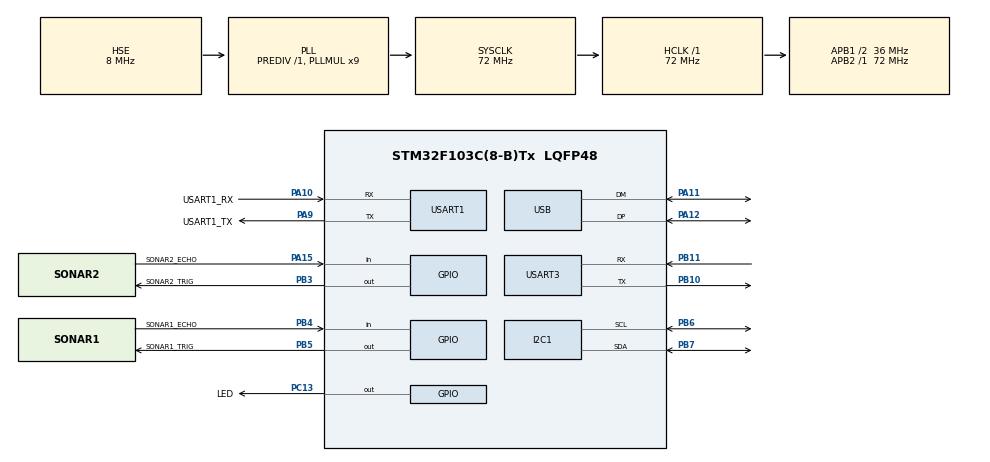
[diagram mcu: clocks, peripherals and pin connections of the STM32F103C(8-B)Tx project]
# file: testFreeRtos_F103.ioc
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FREERTOS.Tasks01=defaultTask,24,128,StartDefaultTask,Default,NULL,Dynamic,NULL,NULL;tsk_screen,8,512,tsk_screen_fn,Default,NULL,Dynamic,NULL,NULL;tsk_sensors,8,256,tsk_sensors_fn,Default,NULL,Dynamic,NULL,NULL
FREERTOS.Timers01=tmr_1,tmr_1_cb,osTimerPeriodic,Default,NULL,Dynamic,NULL
FREERTOS.configTOTAL_HEAP_SIZE=5120
FREERTOS.configUSE_NEWLIB_REENTRANT=1
I2C1.I2C_Mode=I2C_Fast
Mcu.Family=STM32F1
Mcu.Name=STM32F103C(8-B)Tx
Mcu.Package=LQFP48
NVIC.PriorityGroup=NVIC_PRIORITYGROUP_4
NVIC.TIM4_IRQn=true\:15\:0\:false\:false\:true\:false\:false\:true\:true
NVIC.TimeBase=TIM4_IRQn
NVIC.TimeBaseIP=TIM4
NVIC.USB_HP_CAN1_TX_IRQn=true\:5\:0\:false\:false\:true\:true\:true\:true\:true
NVIC.USB_LP_CAN1_RX0_IRQn=true\:5\:0\:false\:false\:true\:true\:false\:true\:true
PA10.GPIO_Label=USART1_RX
PA10.Mode=Asynchronous
PA10.Signal=USART1_RX
PA11.Mode=Device
PA11.Signal=USB_DM
PA12.Mode=Device
PA12.Signal=USB_DP
PA13.Mode=Serial_Wire
PA13.Signal=SYS_JTMS-SWDIO
PA14.Mode=Serial_Wire
PA14.Signal=SYS_JTCK-SWCLK
PA15.GPIO_Label=SONAR2_ECHO
PA15.Signal=GPIO_Input
PA9.GPIO_Label=USART1_TX
PA9.Mode=Asynchronous
PA9.Signal=USART1_TX
PB10.Mode=Asynchronous
PB10.Signal=USART3_TX
PB11.Mode=Asynchronous
PB11.Signal=USART3_RX
PB3.GPIO_Label=SONAR2_TRIG
PB3.Signal=GPIO_Output
PB4.GPIO_Label=SONAR1_ECHO
PB4.Signal=GPIO_Input
PB5.GPIO_Label=SONAR1_TRIG
PB5.Signal=GPIO_Output
PB6.Mode=I2C
PB6.Signal=I2C1_SCL
PB7.Mode=I2C
PB7.Signal=I2C1_SDA
PC13-TAMPER-RTC.GPIO_Label=LED
PC13-TAMPER-RTC.Signal=GPIO_Output
PD0-OSC_IN.Mode=HSE-External-Oscillator
PD0-OSC_IN.Signal=RCC_OSC_IN
PD1-OSC_OUT.Mode=HSE-External-Oscillator
PD1-OSC_OUT.Signal=RCC_OSC_OUT
ProjectManager.HeapSize=0x200
ProjectManager.StackSize=0x400
ProjectManager.TargetToolchain=STM32CubeIDE
RCC.ADCPresc=RCC_ADCPCLK2_DIV4
RCC.AHBFreq_Value=72000000
RCC.APB1CLKDivider=RCC_HCLK_DIV2
RCC.APB1Freq_Value=36000000
RCC.APB1TimFreq_Value=72000000
RCC.APB2Freq_Value=72000000
RCC.APB2TimFreq_Value=72000000
RCC.HCLKFreq_Value=72000000
RCC.PLLMUL=RCC_PLL_MUL9
RCC.SYSCLKFreq_VALUE=72000000
RCC.SYSCLKSource=RCC_SYSCLKSOURCE_PLLCLK
RCC.USBFreq_Value=48000000
RCC.USBPrescaler=RCC_USBCLKSOURCE_PLL_DIV1_5
TIM1.Prescaler=71
USART1.VirtualMode=VM_ASYNC
USART3.VirtualMode=VM_ASYNC
USB_DEVICE.CLASS_NAME_FS=AUDIO
USB_DEVICE.PRODUCT_STRING_AUDIO_FS=STM32 Midi Controller
USB_DEVICE.VirtualMode=Audio
USB_DEVICE.VirtualModeFS=Audio_FS
VP_FREERTOS_VS_CMSIS_V2.Mode=CMSIS_V2
VP_SYS_VS_tim4.Mode=TIM4
VP_TIM1_VS_ClockSourceINT.Mode=Internal
VP_USB_DEVICE_VS_USB_DEVICE_AUDIO_FS.Mode=AUDIO_FS
board=custom

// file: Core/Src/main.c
/* USER CODE BEGIN Header */
/**
  ******************************************************************************
  * @file           : main.c
  * @brief          : Main program body
  ******************************************************************************
  * @attention
  *
  * Copyright (c) 2022 STMicroelectronics.
  * All rights reserved.
  *
  * This software is licensed under terms that can be found in the LICENSE file
  * in the root directory of this software component.
  * If no LICENSE file comes with this software, it is provided AS-IS.
  *
  ******************************************************************************
  */
/* USER CODE END Header */
#include "main.h"
#include "cmsis_os.h"
#include "usb_device.h"

 I2C_HandleTypeDef hi2c1;

TIM_HandleTypeDef htim1;

UART_HandleTypeDef huart1;
UART_HandleTypeDef huart3;

/* Definitions for defaultTask */
osThreadId_t defaultTaskHandle;
const osThreadAttr_t defaultTask_attributes = {
  .name = "defaultTask",
  .stack_size = 128 * 4,
  .priority = (osPriority_t) osPriorityNormal,
};
/* Definitions for tsk_screen */
osThreadId_t tsk_screenHandle;
const osThreadAttr_t tsk_screen_attributes = {
  .name = "tsk_screen",
  .stack_size = 512 * 4,
  .priority = (osPriority_t) osPriorityLow,
};
/* Definitions for tsk_sensors */
osThreadId_t tsk_sensorsHandle;
const osThreadAttr_t tsk_sensors_attributes = {
  .name = "tsk_sensors",
  .stack_size = 256 * 4,
  .priority = (osPriority_t) osPriorityLow,
};
/* Definitions for tmr_1 */
osTimerId_t tmr_1Handle;
const osTimerAttr_t tmr_1_attributes = {
  .name = "tmr_1"
};

void SystemClock_Config(void);
static void MX_GPIO_Init(void);
static void MX_USART1_UART_Init(void);
static void MX_USART3_UART_Init(void);
static void MX_I2C1_Init(void);
static void MX_TIM1_Init(void);
void StartDefaultTask(void *argument);
void tsk_screen_fn(void *argument);
void tsk_sensors_fn(void *argument);
void tmr_1_cb(void *argument);

int main(void)
{

  /* MCU Configuration--------------------------------------------------------*/

  /* Reset of all peripherals, Initializes the Flash interface and the Systick. */
  HAL_Init();

  /* Configure the system clock */
  SystemClock_Config();

  /* Initialize all configured peripherals */
  MX_GPIO_Init();
  MX_USART1_UART_Init();
  MX_USART3_UART_Init();
  MX_I2C1_Init();
  MX_TIM1_Init();

  /* Init scheduler */
  osKernelInitialize();

  /* Create the timer(s) */
  /* creation of tmr_1 */
  tmr_1Handle = osTimerNew(tmr_1_cb, osTimerPeriodic, NULL, &tmr_1_attributes);

  /* Create the thread(s) */
  /* creation of defaultTask */
  defaultTaskHandle = osThreadNew(StartDefaultTask, NULL, &defaultTask_attributes);

  /* creation of tsk_screen */
  tsk_screenHandle = osThreadNew(tsk_screen_fn, NULL, &tsk_screen_attributes);

  /* creation of tsk_sensors */
  tsk_sensorsHandle = osThreadNew(tsk_sensors_fn, NULL, &tsk_sensors_attributes);

  /* Start scheduler */
  osKernelStart();

  /* We should never get here as control is now taken by the scheduler */
  /* Infinite loop */
  while (1)
  {

  }
}

void SystemClock_Config(void)
{
  RCC_OscInitTypeDef RCC_OscInitStruct = {0};
  RCC_ClkInitTypeDef RCC_ClkInitStruct = {0};
  RCC_PeriphCLKInitTypeDef PeriphClkInit = {0};

  /** Initializes the RCC Oscillators according to the specified parameters
  * in the RCC_OscInitTypeDef structure.
  */
  RCC_OscInitStruct.OscillatorType = RCC_OSCILLATORTYPE_HSE;
  RCC_OscInitStruct.HSEState = RCC_HSE_ON;
  RCC_OscInitStruct.HSEPredivValue = RCC_HSE_PREDIV_DIV1;
  RCC_OscInitStruct.HSIState = RCC_HSI_ON;
  RCC_OscInitStruct.PLL.PLLState = RCC_PLL_ON;
  RCC_OscInitStruct.PLL.PLLSource = RCC_PLLSOURCE_HSE;
  RCC_OscInitStruct.PLL.PLLMUL = RCC_PLL_MUL9;
  if (HAL_RCC_OscConfig(&RCC_OscInitStruct) != HAL_OK)
  {
    Error_Handler();
  }

  /** Initializes the CPU, AHB and APB buses clocks
  */
  RCC_ClkInitStruct.ClockType = RCC_CLOCKTYPE_HCLK|RCC_CLOCKTYPE_SYSCLK
                              |RCC_CLOCKTYPE_PCLK1|RCC_CLOCKTYPE_PCLK2;
  RCC_ClkInitStruct.SYSCLKSource = RCC_SYSCLKSOURCE_PLLCLK;
  RCC_ClkInitStruct.AHBCLKDivider = RCC_SYSCLK_DIV1;
  RCC_ClkInitStruct.APB1CLKDivider = RCC_HCLK_DIV2;
  RCC_ClkInitStruct.APB2CLKDivider = RCC_HCLK_DIV1;

  if (HAL_RCC_ClockConfig(&RCC_ClkInitStruct, FLASH_LATENCY_2) != HAL_OK)
  {
    Error_Handler();
  }
  PeriphClkInit.PeriphClockSelection = RCC_PERIPHCLK_USB;
  PeriphClkInit.UsbClockSelection = RCC_USBCLKSOURCE_PLL_DIV1_5;
  if (HAL_RCCEx_PeriphCLKConfig(&PeriphClkInit) != HAL_OK)
  {
    Error_Handler();
  }
}

static void MX_I2C1_Init(void)
{

  hi2c1.Instance = I2C1;
  hi2c1.Init.ClockSpeed = 400000;
  hi2c1.Init.DutyCycle = I2C_DUTYCYCLE_2;
  hi2c1.Init.OwnAddress1 = 0;
  hi2c1.Init.AddressingMode = I2C_ADDRESSINGMODE_7BIT;
  hi2c1.Init.DualAddressMode = I2C_DUALADDRESS_DISABLE;
  hi2c1.Init.OwnAddress2 = 0;
  hi2c1.Init.GeneralCallMode = I2C_GENERALCALL_DISABLE;
  hi2c1.Init.NoStretchMode = I2C_NOSTRETCH_DISABLE;
  if (HAL_I2C_Init(&hi2c1) != HAL_OK)
  {
    Error_Handler();
  }

}

static void MX_TIM1_Init(void)
{

  TIM_ClockConfigTypeDef sClockSourceConfig = {0};
  TIM_MasterConfigTypeDef sMasterConfig = {0};

  htim1.Instance = TIM1;
  htim1.Init.Prescaler = 71;
  htim1.Init.CounterMode = TIM_COUNTERMODE_UP;
  htim1.Init.Period = 65535;
  htim1.Init.ClockDivision = TIM_CLOCKDIVISION_DIV1;
  htim1.Init.RepetitionCounter = 0;
  htim1.Init.AutoReloadPreload = TIM_AUTORELOAD_PRELOAD_DISABLE;
  if (HAL_TIM_Base_Init(&htim1) != HAL_OK)
  {
    Error_Handler();
  }
  sClockSourceConfig.ClockSource = TIM_CLOCKSOURCE_INTERNAL;
  if (HAL_TIM_ConfigClockSource(&htim1, &sClockSourceConfig) != HAL_OK)
  {
    Error_Handler();
  }
  sMasterConfig.MasterOutputTrigger = TIM_TRGO_RESET;
  sMasterConfig.MasterSlaveMode = TIM_MASTERSLAVEMODE_DISABLE;
  if (HAL_TIMEx_MasterConfigSynchronization(&htim1, &sMasterConfig) != HAL_OK)
  {
    Error_Handler();
  }

}

static void MX_USART1_UART_Init(void)
{

  huart1.Instance = USART1;
  huart1.Init.BaudRate = 115200;
  huart1.Init.WordLength = UART_WORDLENGTH_8B;
  huart1.Init.StopBits = UART_STOPBITS_1;
  huart1.Init.Parity = UART_PARITY_NONE;
  huart1.Init.Mode = UART_MODE_TX_RX;
  huart1.Init.HwFlowCtl = UART_HWCONTROL_NONE;
  huart1.Init.OverSampling = UART_OVERSAMPLING_16;
  if (HAL_UART_Init(&huart1) != HAL_OK)
  {
    Error_Handler();
  }

}

static void MX_USART3_UART_Init(void)
{

  huart3.Instance = USART3;
  huart3.Init.BaudRate = 115200;
  huart3.Init.WordLength = UART_WORDLENGTH_8B;
  huart3.Init.StopBits = UART_STOPBITS_1;
  huart3.Init.Parity = UART_PARITY_NONE;
  huart3.Init.Mode = UART_MODE_TX_RX;
  huart3.Init.HwFlowCtl = UART_HWCONTROL_NONE;
  huart3.Init.OverSampling = UART_OVERSAMPLING_16;
  if (HAL_UART_Init(&huart3) != HAL_OK)
  {
    Error_Handler();
  }

}

static void MX_GPIO_Init(void)
{
  GPIO_InitTypeDef GPIO_InitStruct = {0};

  /* GPIO Ports Clock Enable */
  __HAL_RCC_GPIOC_CLK_ENABLE();
  __HAL_RCC_GPIOD_CLK_ENABLE();
  __HAL_RCC_GPIOB_CLK_ENABLE();
  __HAL_RCC_GPIOA_CLK_ENABLE();

  /*Configure GPIO pin Output Level */
  HAL_GPIO_WritePin(LED_GPIO_Port, LED_Pin, GPIO_PIN_RESET);

  /*Configure GPIO pin Output Level */
  HAL_GPIO_WritePin(GPIOB, SONAR2_TRIG_Pin|SONAR1_TRIG_Pin, GPIO_PIN_RESET);

  /*Configure GPIO pin : LED_Pin */
  GPIO_InitStruct.Pin = LED_Pin;
  GPIO_InitStruct.Mode = GPIO_MODE_OUTPUT_PP;
  GPIO_InitStruct.Pull = GPIO_NOPULL;
  GPIO_InitStruct.Speed = GPIO_SPEED_FREQ_LOW;
  HAL_GPIO_Init(LED_GPIO_Port, &GPIO_InitStruct);

  /*Configure GPIO pin : SONAR2_ECHO_Pin */
  GPIO_InitStruct.Pin = SONAR2_ECHO_Pin;
  GPIO_InitStruct.Mode = GPIO_MODE_INPUT;
  GPIO_InitStruct.Pull = GPIO_NOPULL;
  HAL_GPIO_Init(SONAR2_ECHO_GPIO_Port, &GPIO_InitStruct);

  /*Configure GPIO pins : SONAR2_TRIG_Pin SONAR1_TRIG_Pin */
  GPIO_InitStruct.Pin = SONAR2_TRIG_Pin|SONAR1_TRIG_Pin;
  GPIO_InitStruct.Mode = GPIO_MODE_OUTPUT_PP;
  GPIO_InitStruct.Pull = GPIO_NOPULL;
  GPIO_InitStruct.Speed = GPIO_SPEED_FREQ_LOW;
  HAL_GPIO_Init(GPIOB, &GPIO_InitStruct);

  /*Configure GPIO pin : SONAR1_ECHO_Pin */
  GPIO_InitStruct.Pin = SONAR1_ECHO_Pin;
  GPIO_InitStruct.Mode = GPIO_MODE_INPUT;
  GPIO_InitStruct.Pull = GPIO_NOPULL;
  HAL_GPIO_Init(SONAR1_ECHO_GPIO_Port, &GPIO_InitStruct);

}

void StartDefaultTask(void *argument)
{
  /* init code for USB_DEVICE */
  MX_USB_DEVICE_Init();
  /* USER CODE BEGIN 5 */
  /* Infinite loop */
  for(;;)
  {
	  HAL_GPIO_TogglePin(LED_GPIO_Port, LED_Pin);
	  osDelay(100);
  }
  /* USER CODE END 5 */
}

void tsk_screen_fn(void *argument)
{
  for(;;)
  {
    osDelay(1);
  }
}

void tsk_sensors_fn(void *argument)
{
  for(;;)
  {
    osDelay(1);
  }
}

/* tmr_1_cb function */
void tmr_1_cb(void *argument)
{
}

void HAL_TIM_PeriodElapsedCallback(TIM_HandleTypeDef *htim)
{
  if (htim->Instance == TIM4) {
    HAL_IncTick();
  }
}

void Error_Handler(void)
{
  __disable_irq();
  while (1)
  {
  }
}
